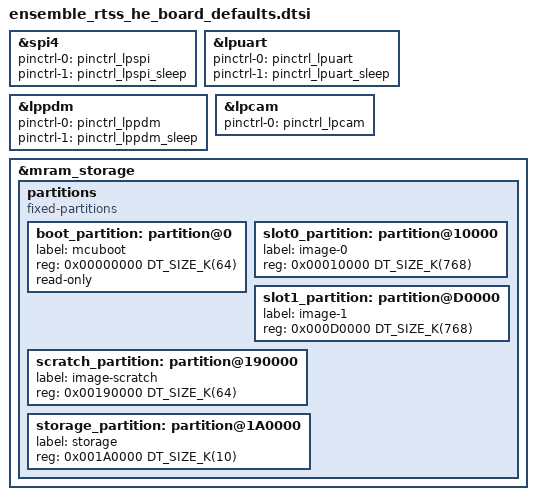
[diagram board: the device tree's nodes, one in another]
/* Copyright (c) 2025 Alif Semiconductor
 *
 * SPDX-License-Identifier: Apache-2.0
 */

&spi4 {
	pinctrl-0 = < &pinctrl_lpspi >;
	pinctrl-1 = < &pinctrl_lpspi_sleep >;
	pinctrl-names = "default", "sleep";
};

&lpuart {
	pinctrl-0 = <&pinctrl_lpuart>;
	pinctrl-1 = <&pinctrl_lpuart_sleep>;
	pinctrl-names = "default", "sleep";
};

&lppdm {
	pinctrl-0 = <&pinctrl_lppdm>;
	pinctrl-1 = <&pinctrl_lppdm_sleep>;
	pinctrl-names = "default", "sleep";
};

&lpcam {
	pinctrl-0 = <&pinctrl_lpcam>;
	pinctrl-names = "default";
};

&mram_storage {
	partitions {
		compatible = "fixed-partitions";
		#address-cells = <1>;
		#size-cells = <1>;
		boot_partition: partition@0 {
			label = "mcuboot";
			reg = <0x00000000 DT_SIZE_K(64)>;
			read-only;
		};
		slot0_partition: partition@10000 {
			label = "image-0";
			reg = <0x00010000 DT_SIZE_K(768)>;
		};
		slot1_partition: partition@D0000 {
			label = "image-1";
			reg = <0x000D0000 DT_SIZE_K(768)>;
		};
		scratch_partition: partition@190000 {
			label = "image-scratch";
			reg = <0x00190000 DT_SIZE_K(64)>;
		};
		storage_partition: partition@1A0000 {
			label = "storage";
			reg = <0x001A0000 DT_SIZE_K(10)>;
		};
	};
};
